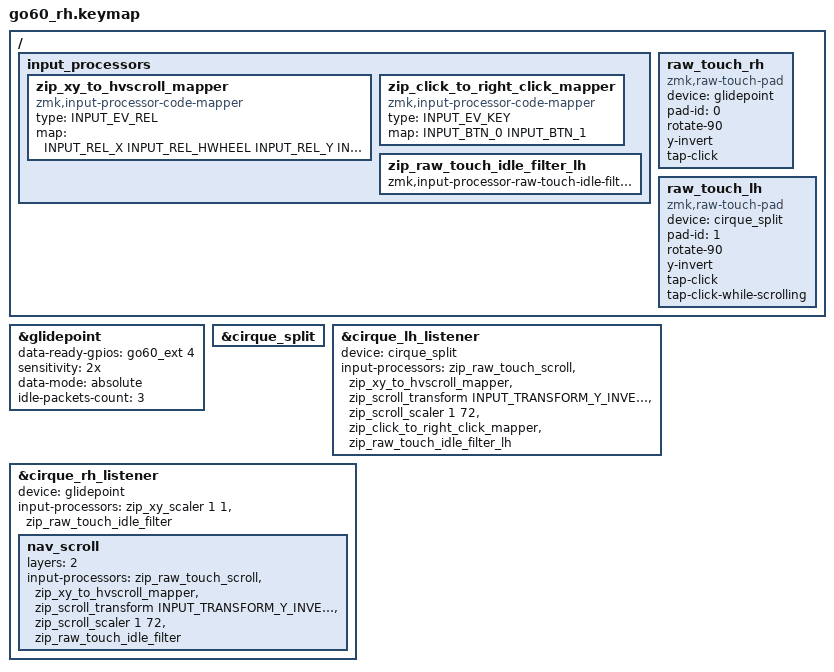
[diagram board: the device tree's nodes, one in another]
#define ZMK_POINTING_DEFAULT_MOVE_VAL 1200
#define ZMK_POINTING_DEFAULT_SCRL_VAL 25

#include <input/processors.dtsi>
#include <raw_touch/processors.dtsi>
#include <zephyr/dt-bindings/input/input-event-codes.h>
#include <zephyr/dt-bindings/gpio/gpio.h>
#include <dt-bindings/zmk/input_transform.h>

#include "positions_go60.dtsi"
#include "shared.dtsi"

/* ── Go60-specific: custom input processor + trackpad listeners ── */

/ {
    input_processors {
        /* Two-axis scroll mapper for the Standard-mode wheel fallback:
         * finger X -> horizontal wheel, finger Y -> vertical wheel.
         * (It replaced a one-axis mapper that sent BOTH axes to
         * REL_WHEEL, so sideways motion scrolled the page vertically.)
         *
         * Deliberately NOT called zip_xy_to_scroll_mapper: newer ZMK -
         * including the pinned MoErgo tree - ships a node with exactly
         * that label (and an identical map) in input/processors.dtsi, and
         * a duplicate label is a build error. The stock node would do,
         * but keeping our own keeps this file independent of which ZMK
         * revision west resolves. */
        zip_xy_to_hvscroll_mapper: zip_xy_to_hvscroll_mapper {
            compatible = "zmk,input-processor-code-mapper";
            #input-processor-cells = <0>;
            type = <INPUT_EV_REL>;
            map = <INPUT_REL_X INPUT_REL_HWHEEL
                   INPUT_REL_Y INPUT_REL_WHEEL>;
        };

        zip_click_to_right_click_mapper: zip_click_to_right_click_mapper {
            compatible = "zmk,input-processor-code-mapper";
            #input-processor-cells = <0>;
            type = <INPUT_EV_KEY>;
            map = <INPUT_BTN_0 INPUT_BTN_1>;
        };

        /* Second idle-filter instance for the left pad's listener. The
         * filter keeps per-node state, so the module's rule is one node
         * per listener - never share an instance across listeners. (The
         * scroll MARKER below is per-device-latched and safe to share;
         * the left pad's base chain and the right pad's nav_scroll
         * overlay both reuse &zip_raw_touch_scroll.) */
        zip_raw_touch_idle_filter_lh: zip_raw_touch_idle_filter_lh {
            compatible = "zmk,input-processor-raw-touch-idle-filter";
            #input-processor-cells = <0>;
        };
    };
};

/* Lower the right pad's ADC gain from the stock maximum ("1x" = most
 * sensitive). The pad's capacitive baseline drifts under sustained touch
 * and at max gain the drift shows up as a jumpy cursor until a no-touch
 * recalibration. "2x" matches MoErgo's "medium" sensitivity snippet.
 *
 * abs-mode switches the Pinnacle to absolute reporting for the raw touch
 * stream (see docs/raw-touch-protocol.md). Requires
 * CONFIG_ZMK_RAW_TOUCH=y (go60_rh.conf): the raw touch module turns
 * the absolute frames back into REL_X/REL_Y for normal pointing, so
 * without it the pad would stop moving the cursor.
 *
 * Tap-to-click and the pad's geometry now live on the raw_touch_rh node
 * below, not here: the module reads them from its own binding so it does
 * not depend on any particular trackpad driver. */
&glidepoint {
    /* MoErgo's Go60 board DTS sets these four on &glidepoint under the
     * forked driver's names. Zephyr 3.5's edtlib errors on properties a
     * binding does not declare, so they must be deleted before the
     * in-tree names are set. */
    /delete-property/ dr-gpios;
    /delete-property/ rotate-90;
    /delete-property/ y-invert;
    /delete-property/ no-secondary-tap;

    data-ready-gpios = <&go60_ext 4 (GPIO_ACTIVE_HIGH | GPIO_PULL_DOWN)>;

    sensitivity = "2x";

    /* Absolute reporting, for the raw touch stream. */
    data-mode = "absolute";


    /* MANDATORY. Written to the Pinnacle's Z_IDLE register; upstream
     * DEFAULTS IT TO 0, which emits no lift-off packets at all - the
     * module would never see a release, so no release frame, no momentum
     * and no tap-to-click. The forked driver hardcoded 3 in absolute
     * mode. */
    idle-packets-count = <3>;

    /* Deliberately NOT setting swap-xy / invert-y here, unlike the left
     * pad below. Upstream applies invert-x/invert-y in BOTH modes (the
     * fork applied them in relative mode only), so setting invert-y would
     * bake the mirror into the streamed absolute frames. Frames must stay
     * raw: the orientation is declared on raw_touch_rh instead, where the
     * module applies it to the derived pointer deltas and publishes it in
     * the feature report for the host. swap-xy is inert in absolute mode
     * either way. */
};

/* The streaming pad. This node is what enables CONFIG_ZMK_RAW_TOUCH, and
 * it is the module's entire configuration surface - nothing about the
 * Cirque driver appears in it.
 *
 * rotate-90 / y-invert MUST match what the Go60 board DTS sets on
 * &glidepoint. Streamed frames go out untransformed and these bits are
 * published in the feature report so the host can apply them; they are
 * also applied to the relative deltas the module derives for the fallback
 * pointer path.
 *
 * tap-click is the firmware replacement for the pad's hardware
 * tap-to-click, which is a relative-mode feature and is lost in abs-mode.
 * Taps inject BTN_0 into this pad's listener chain, which must NOT contain
 * &zip_button_behaviors - that processor exists to map BTN_0 to &none (it
 * was added to mute the relative-mode hardware taps) and would eat the
 * firmware tap. With it removed, BTN_0 flows to the listener's native
 * button handling and clicks on any layer.
 * Defaults: 180 ms, 30 counts max movement - set tap-max-ms /
 * tap-max-movement to tune. */
/ {
    raw_touch_rh: raw_touch_rh {
        compatible = "zmk,raw-touch-pad";
        device = <&glidepoint>;
        pad-id = <0>;
        rotate-90;
        y-invert;
        tap-click;
    };

    /* The left pad, streaming as pad-id 1. Its absolute frames arrive on
     * the central via the split relay (&cirque_split); the orientation
     * bits match the right pad's (both pads are mounted the same way) and
     * the geometry defaults apply.
     *
     * tap-click WITH tap-click-while-scrolling: this is a dedicated scroll
     * pad (see &cirque_lh_listener below), so every touch is scroll
     * context and the module would otherwise veto its taps. With the
     * property a tap is reported anyway and the chain's mapper turns it
     * into a right click, as MoErgo's stock keymap does. In RawTouch mode
     * the module parks the tap and RawTouch confirms it only if the touch
     * did not catch a coast (module README, "Tap confirm"), so a dab that
     * stops momentum never clicks. Hardware-verified 2026-09-23. */
    raw_touch_lh: raw_touch_lh {
        compatible = "zmk,raw-touch-pad";
        device = <&cirque_split>;    /* LH pad arrives via the split relay */
        pad-id = <1>;
        rotate-90;
        y-invert;
        tap-click;
        tap-click-while-scrolling;
    };
};

/* ── Override: right half is now central ── */
/* Remove device from cirque_split (central receives, doesn't send) */
&cirque_split {
    /delete-property/ device;
};

/* Enable listeners with swapped device assignments.
 *
 * ── The LEFT pad is a DEDICATED SCROLL PAD (2026-09-15) ──
 *
 * &zip_raw_touch_scroll lives in its BASE chain, so every touch on this
 * pad is scroll context on every layer - no layer to hold, and no pointer
 * motion from this pad at all any more. There is no nav_scroll overlay:
 * it would be an exact duplicate of the base chain.
 *
 * The chain is dual-purpose exactly as the right pad's overlay is:
 *   - &zip_raw_touch_scroll marks the scroll context, so the streamed
 *     frames carry the scroll-mode flag and RawTouch synthesizes smooth
 *     two-axis scrolling with lift-off momentum from them. In RawTouch
 *     mode the module does not inject scroll-context deltas at all, so
 *     everything after the marker falls silent - no doubled scrolling.
 *   - The wheel chain is the Standard-mode fallback (no host software):
 *     X -> REL_HWHEEL, Y -> REL_WHEEL, scaled 1:72. See the right pad's
 *     comment for where the divisor comes from.
 *
 * Fallback signs, Y_INVERT only: the module's derived deltas are already
 * oriented (logical +X = finger right, +Y = finger down). REL_WHEEL
 * positive means scroll UP, so Y is inverted to get the old-school
 * direction (finger down -> scroll down); REL_HWHEEL positive means
 * scroll RIGHT, which already matches finger-right, so X is left alone.
 * macOS Natural Scrolling then flips both. Both directions were confirmed
 * on hardware 2026-09-15 (docs/next-steps.md item s).
 *
 * As on the right pad: no &zip_button_behaviors, and this listener's OWN
 * idle-filter instance stays LAST - the filter keeps per-node state and
 * must not be shared with the right pad's listener. The right-click
 * mapper sits before it: the pad's taps (tap-click-while-scrolling on
 * raw_touch_lh above) arrive here as BTN_0 and leave as BTN_1. */
&cirque_lh_listener {
    status = "okay";
    device = <&cirque_split>;
    input-processors = <&zip_raw_touch_scroll>,
                       <&zip_xy_to_hvscroll_mapper>,
                       <&zip_scroll_transform INPUT_TRANSFORM_Y_INVERT>,
                       <&zip_scroll_scaler 1 72>,
                       <&zip_click_to_right_click_mapper>,  /* tap -> right click */
                       <&zip_raw_touch_idle_filter_lh>;
};

/* The RIGHT pad keeps the classic arrangement: pointer + tap on the base
 * layer, scrolling while Nav (layer 2) is held.
 *
 * The base chain below sees the REL_X/REL_Y deltas the touch-stream
 * module derives from the absolute frames (plus the ABS frames
 * themselves, which zip_xy_scaler ignores). No zip_button_behaviors
 * here: it would swallow the firmware tap's BTN_0 (see &glidepoint
 * comment). The left pad's chain above has no pointer stage at all.
 *
 * nav_scroll is dual-purpose while Nav is held:
 *   - &zip_raw_touch_scroll marks the scroll context for the raw
 *     touch stream — frames stream with the scroll-mode flag set and the
 *     host (RawTouch, ~/src/rawtouch) synthesizes smooth two-axis
 *     scrolling with lift-off momentum from them. In RawTouch mode the
 *     module stops injecting scroll-context deltas, so the wheel chain
 *     below falls silent on its own.
 *   - The wheel chain still runs as a Standard-mode fallback for hosts
 *     without a stream consumer: X -> REL_HWHEEL and Y -> REL_WHEEL
 *     (two-axis since 2026-09-15; it used to send both axes to
 *     REL_WHEEL), Y inverted for the old-school direction and scaled
 *     1:72 for a sane uncooked rate. See the left pad's comment above
 *     for why only Y is inverted.
 *     (1:24 of the pointer rate, not the 1:8 tuned on 2026-08-19: that
 *     divisor was calibrated against relative-mode deltas, and the deltas
 *     derived from absolute counts run ~3x larger - the same ratio that
 *     took the pointer scaler from 3:1 to 1:1, hence 1:72 written out
 *     against the raw deltas. The divisor only affects this driverless
 *     fallback; the streamed frames bypass the processor chain entirely
 *     and RawTouch does its own scaling on them.)
 */
&cirque_rh_listener {
    status = "okay";
    device = <&glidepoint>;
    /* 1:1, not the relative-mode 3x: pointer deltas here are derived from
     * absolute counts (~38/mm) by the touch-stream module, which run larger
     * than the ASIC's relative-mode output that the 3x was tuned for. */
    input-processors = <&zip_xy_scaler 1 1>,
                       <&zip_raw_touch_idle_filter>;
    nav_scroll {
        layers = <2>;
        /* Order matters: the mapper rewrites REL_X/REL_Y to
         * REL_HWHEEL/REL_WHEEL, so anything after it must target wheel
         * codes (zip_scroll_transform and zip_scroll_scaler both do, and
         * both cover BOTH wheel axes in the pinned ZMK).
         * zip_raw_touch_scroll is a pure pass-through marker; position is
         * irrelevant, but keep it first for visibility. */
        input-processors = <&zip_raw_touch_scroll>,
                           <&zip_xy_to_hvscroll_mapper>,
                           <&zip_scroll_transform INPUT_TRANSFORM_Y_INVERT>,
                           <&zip_scroll_scaler 1 72>,
                           <&zip_raw_touch_idle_filter>;
    };
};
